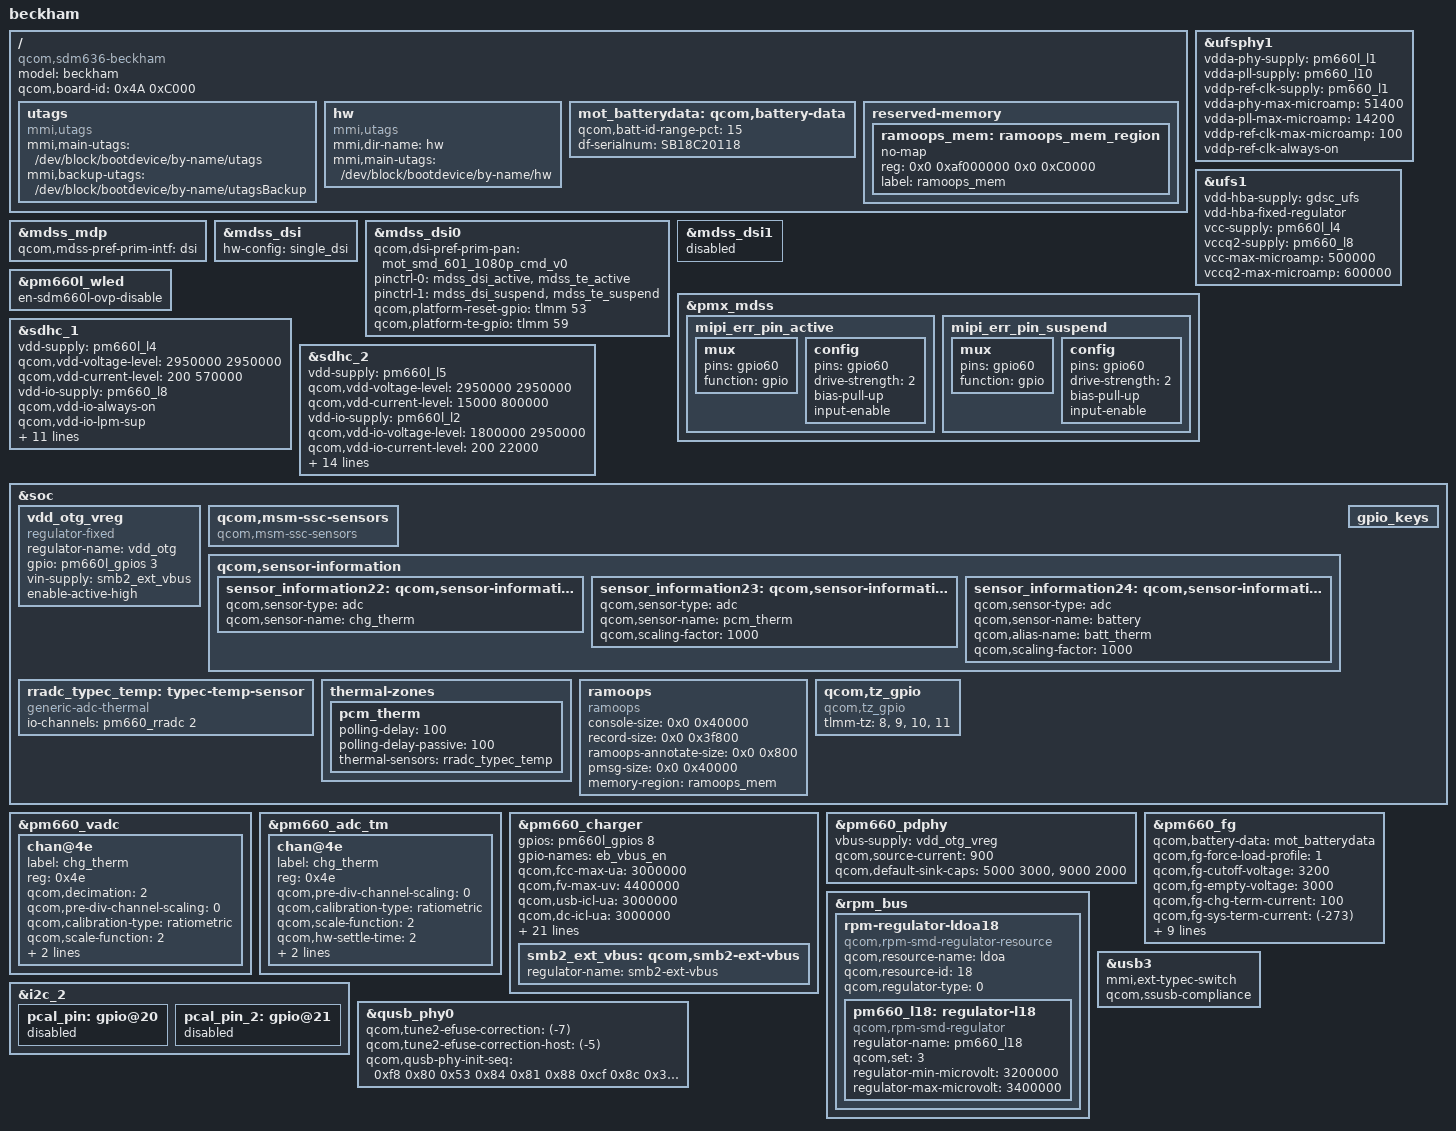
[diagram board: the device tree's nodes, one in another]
/* Copyright (c) 2016, Motorola Mobility Inc. All rights reserved.
 *
 * This program is free software; you can redistribute it and/or modify
 * it under the terms of the GNU General Public License version 2 and
 * only version 2 as published by the Free Software Foundation.
 *
 * This program is distributed in the hope that it will be useful,
 * but WITHOUT ANY WARRANTY; without even the implied warranty of
 * MERCHANTABILITY or FITNESS FOR A PARTICULAR PURPOSE.  See the
 * GNU General Public License for more details.
 */


/dts-v1/;

#include "sdm636.dtsi"
#include "msm-pm660a.dtsi"
#include "sdm660-external-codec.dtsi"
#include "sdm660-beckham-pinctrl.dtsi"
#include "sdm660-moto-pinctrl.dtsi"
#include "sdm660-moto-fps.dtsi"
#include "dsi-panel-mot-smd-601-1080p-cmd.dtsi"
#include "dsi-panel-mot-tianma-601-1080p-cmd.dtsi"
#include "carrier-channel-ids.dtsi"

/ {
        model = "beckham";
        compatible = "qcom,sdm636-beckham", "qcom,sdm636-moto",
                        "qcom,sdm636";
	qcom,board-id = <0x4A 0xC000>;

	utags {
		compatible = "mmi,utags";
		mmi,main-utags = "/dev/block/bootdevice/by-name/utags";
		mmi,backup-utags = "/dev/block/bootdevice/by-name/utagsBackup";
	};

	hw {
		compatible = "mmi,utags";
		mmi,dir-name = "hw";
		mmi,main-utags = "/dev/block/bootdevice/by-name/hw";
	};

	mot_batterydata: qcom,battery-data {
		qcom,batt-id-range-pct = <15>;
		df-serialnum = "SB18C20118";
		#include "batterydata-js40-scud-pm660.dtsi"
		#include "batterydata-js40-swd-pm660.dtsi"
	};

	reserved-memory {
		ramoops_mem: ramoops_mem_region {
			no-map;
			reg = <0x0 0xaf000000 0x0 0xC0000>;
			label = "ramoops_mem";
		};
	};
};

&ufsphy1 {
	vdda-phy-supply = <&pm660l_l1>;
	vdda-pll-supply = <&pm660_l10>;
	vddp-ref-clk-supply = <&pm660_l1>;
	vdda-phy-max-microamp = <51400>;
	vdda-pll-max-microamp = <14200>;
	vddp-ref-clk-max-microamp = <100>;
	vddp-ref-clk-always-on;
	status = "ok";
};

&ufs1 {
	vdd-hba-supply = <&gdsc_ufs>;
	vdd-hba-fixed-regulator;
	vcc-supply = <&pm660l_l4>;
	vccq2-supply = <&pm660_l8>;
	vcc-max-microamp = <500000>;
	vccq2-max-microamp = <600000>;
	status = "ok";
};

&mdss_mdp {
	qcom,mdss-pref-prim-intf = "dsi";
};

&mdss_dsi {
	hw-config = "single_dsi";
};

&mdss_dsi0 {
	qcom,dsi-pref-prim-pan = <&mot_smd_601_1080p_cmd_v0>;
	pinctrl-names = "mdss_default", "mdss_sleep";
	pinctrl-0 = <&mdss_dsi_active &mdss_te_active>;
	pinctrl-1 = <&mdss_dsi_suspend &mdss_te_suspend>;
	qcom,platform-reset-gpio = <&tlmm 53 0>;
	qcom,platform-te-gpio = <&tlmm 59 0>;
};

&mdss_dsi1 {
	status = "disabled";
};

&pmx_mdss {
	mipi_err_pin_active: mipi_err_pin_active {
		mux {
			pins = "gpio60";
			function = "gpio";
		};

		config {
			pins = "gpio60";
			drive-strength = <2>; /* 2 mA */
			bias-pull-up; /* pull up */
			input-enable;
		};
	};

	mipi_err_pin_suspend: mipi_err_pin_suspend {
		mux {
			pins = "gpio60";
			function = "gpio";
		};

		config {
			pins = "gpio60";
			drive-strength = <2>; /* 2 mA */
			bias-pull-up; /* pull up */
			input-enable;
		};
	};
};

&pm660l_wled {
	en-sdm660l-ovp-disable;
};

&sdhc_1 {
	/* device core power supply */
	vdd-supply = <&pm660l_l4>;
	qcom,vdd-voltage-level = <2950000 2950000>;
	qcom,vdd-current-level = <200 570000>;

	/* device communication power supply */
	vdd-io-supply = <&pm660_l8>;
	qcom,vdd-io-always-on;
	qcom,vdd-io-lpm-sup;
	qcom,vdd-io-voltage-level = <1800000 1800000>;
	qcom,vdd-io-current-level = <200 325000>;

	pinctrl-names = "active", "sleep";
	pinctrl-0 = <&sdc1_clk_on &sdc1_cmd_on &sdc1_data_on &sdc1_rclk_on>;
	pinctrl-1 = <&sdc1_clk_off &sdc1_cmd_off &sdc1_data_off &sdc1_rclk_off>;

	qcom,clk-rates = <400000 20000000 25000000 50000000 100000000 192000000
								384000000>;

	qcom,nonremovable;
	qcom,bus-speed-mode = "HS400_1p8v", "HS200_1p8v", "DDR_1p8v";

	status = "ok";
};

&sdhc_2 {
	/* device core power supply */
	vdd-supply = <&pm660l_l5>;
	qcom,vdd-voltage-level = <2950000 2950000>;
	qcom,vdd-current-level = <15000 800000>;

	/* device communication power supply */
	vdd-io-supply = <&pm660l_l2>;
	qcom,vdd-io-voltage-level = <1800000 2950000>;
	qcom,vdd-io-current-level = <200 22000>;

	pinctrl-names = "active", "sleep";
	pinctrl-0 = <&sdc2_clk_on &sdc2_cmd_on &sdc2_data_on &sdc2_cd_on>;
	pinctrl-1 = <&sdc2_clk_off &sdc2_cmd_off &sdc2_data_off &sdc2_cd_off>;

	#address-cells = <0>;
	interrupt-parent = <&sdhc_2>;
	interrupts = <0 1 2>;
	#interrupt-cells = <1>;
	interrupt-map-mask = <0xffffffff>;
	interrupt-map = <0 &intc 0 0 125 0
			1 &intc 0 0 221 0
			2 &tlmm 54 0>;
	interrupt-names = "hc_irq", "pwr_irq", "status_irq";
	cd-gpios = <&tlmm 54 0x1>;

	qcom,clk-rates = <400000 20000000 25000000 50000000 100000000
								200000000>;
	qcom,bus-speed-mode = "SDR12", "SDR25", "SDR50", "DDR50", "SDR104";

	status = "ok";
};

&soc {
	vdd_otg_vreg: vdd_otg_vreg {
		compatible = "regulator-fixed";
		regulator-name = "vdd_otg";
		gpio = <&pm660l_gpios 3 0>;
		vin-supply = <&smb2_ext_vbus>;
		enable-active-high;
	};

	qcom,msm-ssc-sensors {
		compatible = "qcom,msm-ssc-sensors";
	};

	qcom,sensor-information {
		sensor_information22: qcom,sensor-information-22 {
			qcom,sensor-type =  "adc";
			qcom,sensor-name = "chg_therm";
		};
		sensor_information23: qcom,sensor-information-23 {
			qcom,sensor-type =  "adc";
			qcom,sensor-name = "pcm_therm";
			qcom,scaling-factor = <1000>;
		};
		sensor_information24: qcom,sensor-information-24 {
			qcom,sensor-type = "adc";
			qcom,sensor-name = "battery";
			qcom,alias-name  = "batt_therm";
			qcom,scaling-factor = <1000>;
		};
	};

	rradc_typec_temp: typec-temp-sensor {
		compatible = "generic-adc-thermal";
		#thermal-sensor-cells = <0>;
		io-channels = <&pm660_rradc 2>;
		io-channel-names = "sensor-channel";
	};

	thermal-zones {
		pcm_therm {
			polling-delay = <100>; /* milliseconds */
			polling-delay-passive = <100>; /* milliseconds */
			thermal-sensors = <&rradc_typec_temp>;
		};
	};

	ramoops {
		compatible = "ramoops";
		status = "ok";

		console-size = <0x0 0x40000>;
		record-size = <0x0 0x3f800>;
		ramoops-annotate-size = <0x0 0x800>;
		pmsg-size = <0x0 0x40000>;

		memory-region = <&ramoops_mem>;
	};

	qcom,tz_gpio {
		compatible = "qcom,tz_gpio";
		tlmm-tz = <8>,
			<9>,
			<10>,
			<11>;
	};

	gpio_keys {
		/delete-property/ pinctrl-names;
		/delete-property/ pinctrl-0;
		/delete-property/ pinctrl-1;
	};
};

&pm660_vadc {
	chan@4e {
		label = "chg_therm";
		reg = <0x4e>;
		qcom,decimation = <2>;
		qcom,pre-div-channel-scaling = <0>;
		qcom,calibration-type = "ratiometric";
		qcom,scale-function = <2>;
		qcom,hw-settle-time = <2>;
		qcom,fast-avg-setup = <0>;
	};
};

&pm660_adc_tm {
	chan@4e {
		label = "chg_therm";
		reg = <0x4e>;
		qcom,pre-div-channel-scaling = <0>;
		qcom,calibration-type = "ratiometric";
		qcom,scale-function = <2>;
		qcom,hw-settle-time = <2>;
		qcom,btm-channel-number = <0x70>;
		qcom,thermal-node;
	};
};

&pm660_charger {
	gpios = <&pm660l_gpios 8 0x0>; /* GPIOF_OUT_INIT_LOW */
	gpio-names = "eb_vbus_en";
};

&pm660_pdphy {
	vbus-supply = <&vdd_otg_vreg>;
	qcom,source-current = <900>;
	qcom,default-sink-caps = <5000 3000>, /* 5V @ 3A */
				<9000 2000>; /* 9V @ 2A */
};

&pm660_charger {
	qcom,fcc-max-ua = <3000000>;
	qcom,fv-max-uv = <4400000>;
	qcom,usb-icl-ua = <3000000>;
	qcom,dc-icl-ua = <3000000>;
	qcom,eb-batt-psy-name = "gb_battery";
	qcom,eb-pwr-psy-name = "gb_ptp";
	qcom,dc-eb-icl-ma = <900>;
	qcom,dc-eb-icl-eff-ma = <500>;
	qcom,iterm-ma = <146>;
	qcom,thermal-mitigation = <3000>,
				   <2500>,
				   <1500>,
				   <900>,
				   <600>,
				   <300>;
	qcom,dc-thermal-mitigation = <3000>,
				     <1500>,
				     <900>,
				     <600>,
				     <300>;
	qcom,mmi-temp-zones = <0 4200 582 0>,
				<10 4200 1455 582>,
				<15 0 1455 1455>,
				<45 4200 3000 2000>,
				<60 4200 1455 0>;
	qcom,enable-charging-limit;
	qcom,upper-limit-capacity = <75>;
	qcom,lower-limit-capacity = <60>;
	qcom,vfloat-comp-uv = <20000>;
	qcom,usbpd-phandle = <&pm660_pdphy>;
	qcom,source-current-ma = <900>;
	qcom,typec-debounce;
	qcom,external-vconn;
	qcom,external-vbus;
	smb2_ext_vbus: qcom,smb2-ext-vbus {
		regulator-name = "smb2-ext-vbus";
	};
};

&pm660_fg {
	qcom,battery-data = <&mot_batterydata>;
	qcom,fg-force-load-profile = <1>;
	qcom,fg-cutoff-voltage = <3200>;
	qcom,fg-empty-voltage = <3000>;
	qcom,fg-chg-term-current = <100>;
	qcom,fg-sys-term-current = <(-273)>;
	qcom,fg-delta-soc-thr = <1>;
	qcom,fg-jeita-thresholds = <(-20)>, <0>, <45>, <60>;
	qcom,cl-start-capacity = <5>;
	qcom,cl-min-temp = <150>;
	qcom,cl-max-temp = <450>;
	qcom,cl-max-increment = <5>;
	qcom,cl-max-decrement = <10>;
	qcom,cl-min-limit = <200>;
	qcom,cl-max-limit = <30>;
};

&rpm_bus {
	rpm-regulator-ldoa18 {
		compatible = "qcom,rpm-smd-regulator-resource";
		qcom,resource-name = "ldoa";
		qcom,resource-id = <18>;
		qcom,regulator-type = <0>;
		status = "okay";
		pm660_l18: regulator-l18 {
			compatible = "qcom,rpm-smd-regulator";
			regulator-name = "pm660_l18";
			qcom,set = <3>;
			regulator-min-microvolt = <3200000>;
			regulator-max-microvolt = <3400000>;
			status = "okay";
		};
	};
};

&usb3 {
	mmi,ext-typec-switch;
	qcom,ssusb-compliance;
};

&i2c_2 {
	pcal_pin:gpio@20 {
		status = "disabled";
	};

	pcal_pin_2:gpio@21 {
		status = "disabled";
	};
};

&qusb_phy0 {
	qcom,tune2-efuse-correction = <(-7)>;
	qcom,tune2-efuse-correction-host = <(-5)>;
	qcom,qusb-phy-init-seq = <0xf8 0x80
				0x53 0x84
				0x81 0x88
				0xcf 0x8c
				0x30 0x08
				0x79 0x0c
				0x21 0x10
				0x14 0x9c
				0x9f 0x1c
				0x00 0x18>;
};

